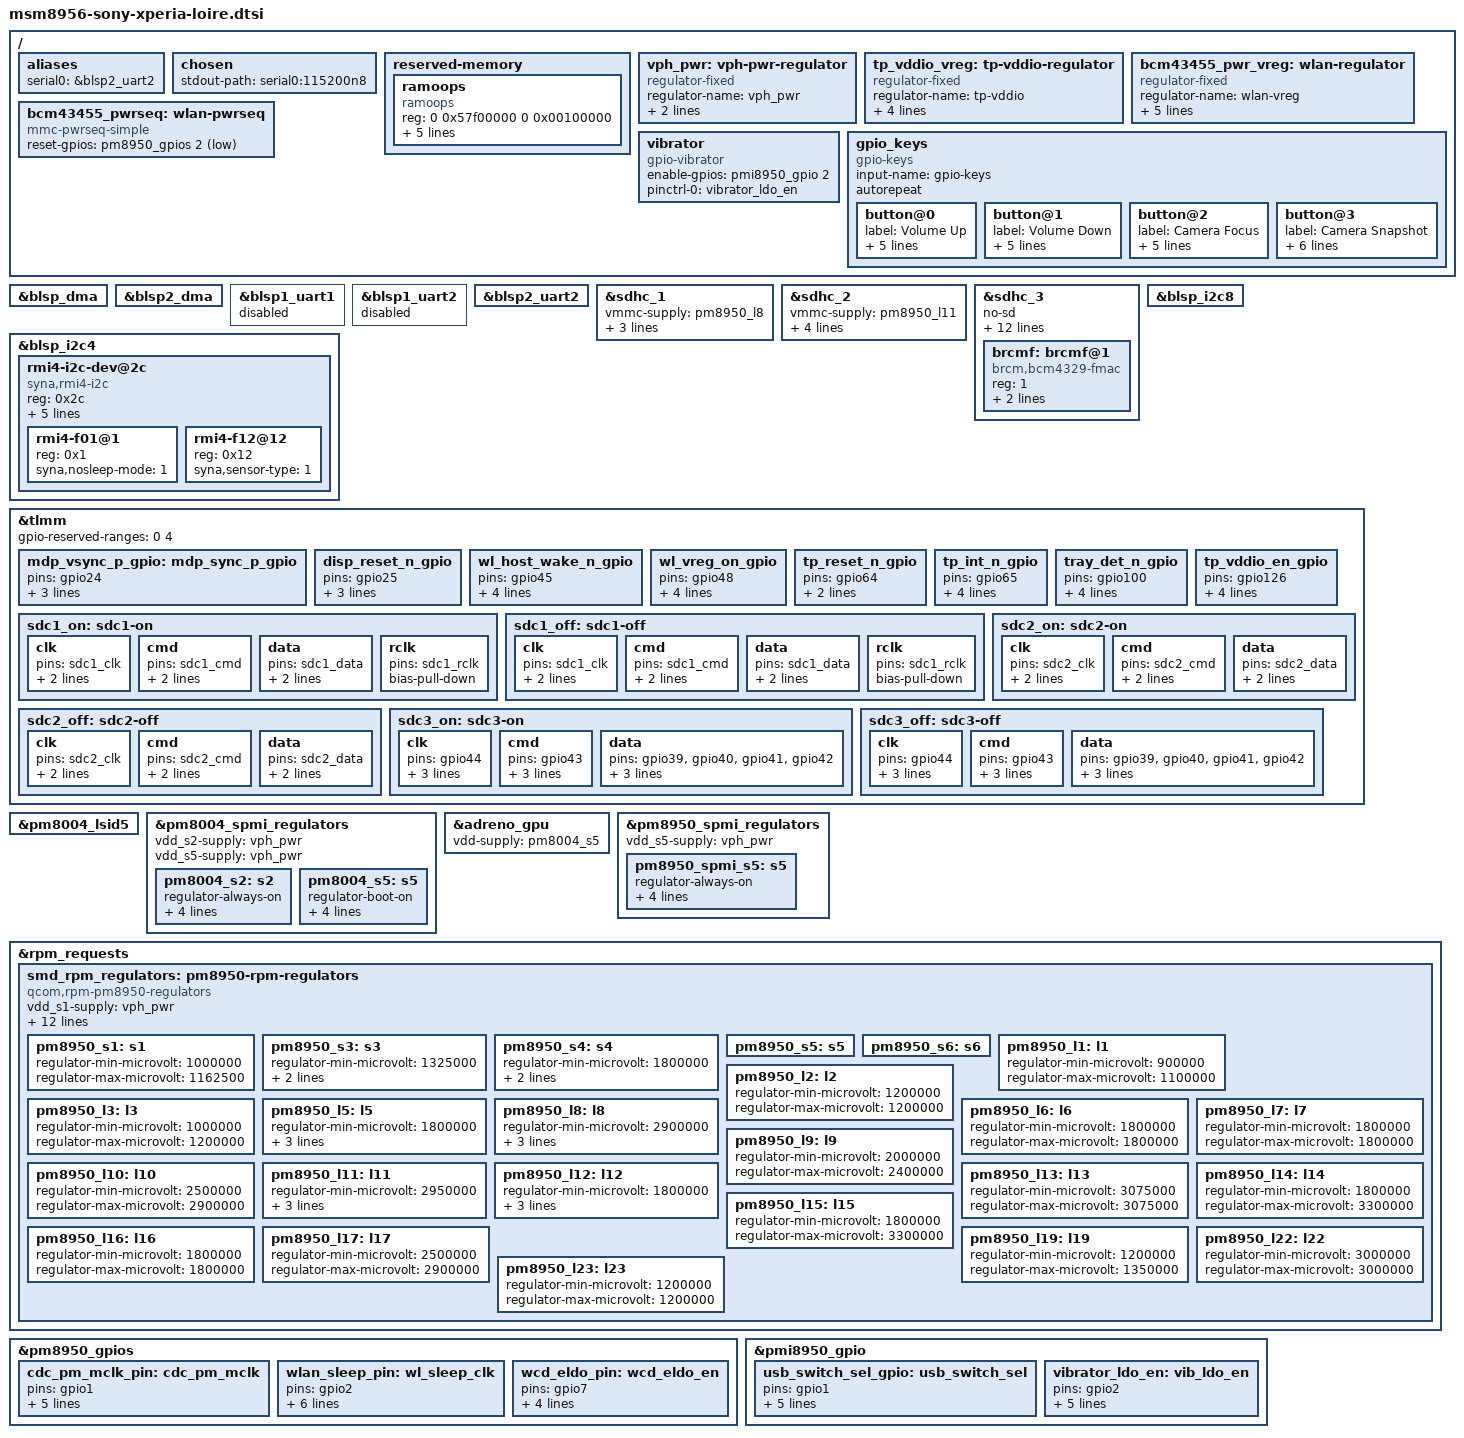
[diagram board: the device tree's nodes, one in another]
// SPDX-License-Identifier: GPL-2.0
/*
 * Sony Xperia Loire/SmartLoire platform (MSM8956/APQ8056) configuration
 * This configuration is common across a range of Xperia devices
 * based on the Loire and SmartLoire projects.
 *
 * Copyright (C) 2014 Sony Mobile Communications Inc.
 * Copyright (c) 2016-2019 AngeloGioacchino Del Regno <kholk11@gmail.com>
 */

#include "msm8976.dtsi"
#include "pmi8950.dtsi"
#include "pm8950.dtsi"
#include "pm8004.dtsi"
#include <dt-bindings/interrupt-controller/irq.h>
#include <dt-bindings/gpio/gpio.h>
#include <dt-bindings/input/gpio-keys.h>
#include <dt-bindings/input/input.h>
#include <dt-bindings/input/linux-event-codes.h>
#include <dt-bindings/pinctrl/qcom,pmic-gpio.h>

/ {
	aliases {
		serial0 = &blsp2_uart2;
	};

	chosen {
		stdout-path = "serial0:115200n8";
	};

	reserved-memory {
		ramoops {
			compatible = "ramoops";
			reg = <0 0x57f00000 0 0x00100000>;
			record-size = <0x20000>;
			console-size = <0x40000>;
			ftrace-size = <0x20000>;
			pmsg-size = <0x20000>;
			ecc-size = <16>;
			status = "ok";
		};
	};

	vph_pwr: vph-pwr-regulator {
		compatible = "regulator-fixed";
		regulator-name = "vph_pwr";
		regulator-always-on;
		regulator-boot-on;
	};

	tp_vddio_vreg: tp-vddio-regulator {
		compatible = "regulator-fixed";

		regulator-name = "tp-vddio";
		regulator-min-microvolt = <1800000>;
		regulator-max-microvolt = <1800000>;

		gpio = <&tlmm 126 GPIO_ACTIVE_HIGH>;

		pinctrl-names = "default";
		pinctrl-0 = <&tp_vddio_en_gpio>;
	};

	bcm43455_pwr_vreg: wlan-regulator {
		compatible = "regulator-fixed";

		regulator-name = "wlan-vreg";
		regulator-min-microvolt = <3300000>;
		regulator-max-microvolt = <3300000>;

		gpio = <&tlmm 48 GPIO_ACTIVE_HIGH>;
		enable-active-high;

		pinctrl-names = "default";
		pinctrl-0 = <&wl_vreg_on_gpio>;
	};

	bcm43455_pwrseq: wlan-pwrseq {
		compatible = "mmc-pwrseq-simple";
		reset-gpios = <&pm8950_gpios 2 GPIO_ACTIVE_LOW>;
	};

	vibrator {
		compatible = "gpio-vibrator";
		enable-gpios = <&pmi8950_gpio 2 GPIO_ACTIVE_HIGH>;

		pinctrl-names = "default";
		pinctrl-0 = <&vibrator_ldo_en>;
	};

	gpio_keys {
		compatible = "gpio-keys";
		input-name = "gpio-keys";
		#address-cells = <1>;
		#size-cells = <0>;
		autorepeat;

		button@0 {
			label = "Volume Up";
			gpios = <&tlmm 130 GPIO_ACTIVE_LOW>;
			linux,input-type = <EV_KEY>;
			linux,code = <KEY_VOLUMEUP>;
			wakeup-source;
			debounce-interval = <15>;
		};

		button@1 {
			label = "Volume Down";
			gpios = <&tlmm 113 GPIO_ACTIVE_LOW>;
			linux,input-type = <EV_KEY>;
			linux,code = <KEY_VOLUMEDOWN>;
			wakeup-source;
			debounce-interval = <15>;
		};

		button@2 {
			label = "Camera Focus";
			gpios = <&tlmm 114 GPIO_ACTIVE_LOW>;
			linux,input-type = <EV_KEY>;
			linux,code = <KEY_CAMERA_FOCUS>;
			wakeup-source;
			debounce-interval = <15>;
		};

		button@3 {
			label = "Camera Snapshot";
			gpios = <&tlmm 115 GPIO_ACTIVE_LOW>;
			linux,input-type = <EV_KEY>;
			linux,code = <KEY_CAMERA>;
			wakeup-source;
			wakeup-event-action = <EV_ACT_ASSERTED>;
			debounce-interval = <15>;
		};
	};
};

&blsp_dma {
	status = "ok";
};

&blsp2_dma {
	status = "ok";
};

&blsp1_uart1 {
	status = "disabled";
};

&blsp1_uart2 {
	status = "disabled";
};

&blsp2_uart2 {
	status = "ok";
};

/* eMMC */
&sdhc_1 {
	vmmc-supply = <&pm8950_l8>;
	vqmmc-supply = <&pm8950_l5>;

	pinctrl-names = "default", "sleep";
	pinctrl-0 = <&sdc1_on>;
	pinctrl-1 = <&sdc1_off>;

	status = "ok";
};

/* MicroSD card slot */
&sdhc_2 {
	vmmc-supply = <&pm8950_l11>;
	vqmmc-supply = <&pm8950_l12>;
	cd-gpios = <&tlmm 100 GPIO_ACTIVE_HIGH>;

	pinctrl-names = "default", "sleep";
	pinctrl-0 = <&sdc2_on &tray_det_n_gpio>;
	pinctrl-1 = <&sdc2_off &tray_det_n_gpio>;

	status = "ok";
};

/* SDIO (internal) to BCM WiFi */
&sdhc_3 {
	status = "ok";
	no-sd;
	no-mmc;

	bus-width = <4>;
	max-frequency = <100000000>;
	keep-power-in-suspend;

	non-removable;
	wakeup-source;
	vmmc-supply = <&bcm43455_pwr_vreg>;
	mmc-pwrseq = <&bcm43455_pwrseq>;

	pinctrl-names = "default", "sleep";
	pinctrl-0 = <&sdc3_on &wlan_sleep_pin &wl_host_wake_n_gpio>;
	pinctrl-1 = <&sdc3_off &wlan_sleep_pin &wl_host_wake_n_gpio>;

	#address-cells = <1>;
	#size-cells = <0>;

	brcmf: brcmf@1 {
		reg = <1>;
		compatible = "brcm,bcm4329-fmac";
		interrupt-parent = <&tlmm>;
		interrupts = <45 IRQ_TYPE_LEVEL_LOW>;
		interrupt-names = "host-wake";
	};
};

&blsp_i2c4 {
	status = "ok";

	rmi4-i2c-dev@2c {
		compatible = "syna,rmi4-i2c";
		reg = <0x2c>;

		interrupt-parent = <&tlmm>;
		interrupts = <65 IRQ_TYPE_EDGE_FALLING>;

		#address-cells = <1>;
		#size-cells = <0>;

		vdd-supply = <&tp_vddio_vreg>;

		syna,reset-delay-ms = <220>;
		syna,startup-delay-ms = <220>;

		rmi4-f01@1 {
			reg = <0x1>;
			syna,nosleep-mode = <1>;
		};

		rmi4-f12@12 {
			reg = <0x12>;
			syna,sensor-type = <1>;
		};
	};
};

&blsp_i2c8 {
	status = "ok";
};

&tlmm {
	gpio-reserved-ranges = <0 4>;

	mdp_vsync_p_gpio: mdp_sync_p_gpio {
		pins = "gpio24";
		function = "mdp_vsync";

		drive-strength = <2>;
		bias-disable;
	};

	disp_reset_n_gpio: disp_reset_n_gpio {
		pins = "gpio25";
		function = "gpio";

		drive-strength = <2>;
		output-high;
	};

	wl_host_wake_n_gpio: wl_host_wake_n_gpio {
		pins = "gpio45";
		function = "gpio";

		drive-strength = <2>;
		bias-pull-down;
		input-enable;
	};

	wl_vreg_on_gpio: wl_vreg_on_gpio {
		pins = "gpio48";
		function = "gpio";

		drive-strength = <2>;
		bias-disable;
		output-high;
	};

	tp_reset_n_gpio: tp_reset_n_gpio {
		pins = "gpio64";
		function = "gpio";

		drive-strength = <2>;
	};

	tp_int_n_gpio: tp_int_n_gpio {
		pins = "gpio65";
		function = "gpio";

		drive-strength = <2>;
		bias-pull-up;
		input-enable;
	};

	tray_det_n_gpio: tray_det_n_gpio {
		pins = "gpio100";
		function = "gpio";

		drive-strength = <2>;
		bias-disable;
		input-enable;
	};

	tp_vddio_en_gpio: tp_vddio_en_gpio {
		pins = "gpio126";
		function = "gpio";

		drive-strength = <2>;
		bias-disable;
		output-low;
	};

	sdc1_on: sdc1-on {
		clk {
			pins = "sdc1_clk";
			bias-disable;
			drive-strength = <16>;
		};

		cmd {
			pins = "sdc1_cmd";
			bias-pull-up;
			drive-strength = <10>;
		};

		data {
			pins = "sdc1_data";
			bias-pull-up;
			drive-strength = <10>;
		};

		rclk {
			pins = "sdc1_rclk";
			bias-pull-down;
		};
	};

	sdc1_off: sdc1-off {
		clk {
			pins = "sdc1_clk";
			bias-disable;
			drive-strength = <2>;
		};

		cmd {
			pins = "sdc1_cmd";
			bias-pull-up;
			drive-strength = <2>;
		};

		data {
			pins = "sdc1_data";
			bias-pull-up;
			drive-strength = <2>;
		};

		rclk {
			pins = "sdc1_rclk";
			bias-pull-down;
		};
	};

	sdc2_on: sdc2-on {
		clk {
			pins = "sdc2_clk";
			bias-disable;
			drive-strength = <16>;
		};

		cmd {
			pins = "sdc2_cmd";
			bias-pull-up;
			drive-strength = <10>;
		};

		data {
			pins = "sdc2_data";
			bias-pull-up;
			drive-strength = <10>;
		};
	};

	sdc2_off: sdc2-off {
		clk {
			pins = "sdc2_clk";
			bias-disable;
			drive-strength = <2>;
		};

		cmd {
			pins = "sdc2_cmd";
			bias-pull-up;
			drive-strength = <2>;
		};

		data {
			pins = "sdc2_data";
			bias-pull-up;
			drive-strength = <2>;
		};
	};

	sdc3_on: sdc3-on {
		clk {
			pins = "gpio44";
			function = "sdc3";
			bias-disable;
			drive-strength = <10>;
		};

		cmd {
			pins = "gpio43";
			function = "sdc3";
			bias-pull-up;
			drive-strength = <10>;
		};

		data {
			pins = "gpio39", "gpio40", "gpio41", "gpio42";
			function = "sdc3";
			bias-pull-up;
			drive-strength = <10>;
		};
	};

	sdc3_off: sdc3-off {
		clk {
			pins = "gpio44";
			function = "sdc3";
			bias-disable;
			drive-strength = <2>;
		};

		cmd {
			pins = "gpio43";
			function = "sdc3";
			bias-pull-up;
			drive-strength = <2>;
		};

		data {
			pins = "gpio39", "gpio40", "gpio41", "gpio42";
			function = "sdc3";
			bias-pull-up;
			drive-strength = <2>;
		};
	};
};

&pm8004_lsid5 {
	status = "ok";
};

&pm8004_spmi_regulators {
	vdd_s2-supply = <&vph_pwr>;
	vdd_s5-supply = <&vph_pwr>;

	/* Cluster 1 supply */
	pm8004_s2: s2 {
		/* Set APC1 always-on and raise min voltage to .95V
		 * until a proper CPU scaling solution lands
		 */
		regulator-always-on;
		regulator-boot-on;
		regulator-name = "vdd_apc1";
		regulator-min-microvolt = <950000>; /* 500000 */
		regulator-max-microvolt = <1165000>;
	};

	pm8004_s5: s5 {
		/* Put GFX VDD up at boot until a proper solution lands */
		regulator-boot-on;

		regulator-name = "vdd_gfx";
		regulator-min-microvolt = <950000>;
		regulator-max-microvolt = <1165000>;
		regulator-enable-ramp-delay = <500>;
	};
};

&adreno_gpu {
	vdd-supply = <&pm8004_s5>;
};

&pm8950_spmi_regulators {
	vdd_s5-supply = <&vph_pwr>;

	/* Cluster 0 supply */
	pm8950_spmi_s5: s5 {
		/* Set APC0 always-on and raise min voltage to .95V
		 * until a proper CPU scaling solution lands
		 */
		regulator-always-on;
		regulator-boot-on;
		regulator-name = "vdd_apc0";
		regulator-min-microvolt = <950000>; /* 790000 */
		regulator-max-microvolt = <1165000>;
	};
};

&rpm_requests {
	smd_rpm_regulators: pm8950-rpm-regulators {
		compatible = "qcom,rpm-pm8950-regulators";
	
		vdd_s1-supply = <&vph_pwr>;
		vdd_s2-supply = <&vph_pwr>;
		vdd_s3-supply = <&vph_pwr>;
		vdd_s4-supply = <&vph_pwr>;
		vdd_s5-supply = <&vph_pwr>;
		vdd_s6-supply = <&vph_pwr>;
		vdd_l1_l19-supply = <&pm8950_s3>;
		vdd_l2_l23-supply = <&pm8950_s3>;
		vdd_l3-supply = <&pm8950_s3>;
		vdd_l4_l5_l6_l7_l16-supply = <&pm8950_s4>;
		vdd_l8_l11_l12_l17_l22-supply = <&vph_pwr>;
		vdd_l20-supply = <&pm8950_s4>;
		vdd_l21-supply = <&pm8950_s4>;
	
		pm8950_s1: s1 {
			regulator-min-microvolt = <1000000>;
			regulator-max-microvolt = <1162500>;
		};
	
		pm8950_s3: s3 {
			regulator-min-microvolt = <1325000>;
			regulator-max-microvolt = <1325000>;
			regulator-always-on;
		};
	
		pm8950_s4: s4 {
			regulator-min-microvolt = <1800000>;
			regulator-max-microvolt = <1800000>;
			regulator-always-on;
		};
	
		pm8950_s5: s5 {};
	
		pm8950_s6: s6 {};
	
		pm8950_l1: l1 {
			regulator-min-microvolt = <900000>;
			regulator-max-microvolt = <1100000>;
		};
	
		pm8950_l2: l2 {
			regulator-min-microvolt = <1200000>;
			regulator-max-microvolt = <1200000>;
		};
	
		pm8950_l3: l3 {
			regulator-min-microvolt = <1000000>;
			regulator-max-microvolt = <1200000>;
		};
	
		pm8950_l5: l5 {
			regulator-min-microvolt = <1800000>;
			regulator-max-microvolt = <1800000>;
	
			regulator-system-load = <300000>;
			regulator-allow-set-load;
		};
	
		pm8950_l6: l6 {
			regulator-min-microvolt = <1800000>;
			regulator-max-microvolt = <1800000>;
		};
	
		pm8950_l7: l7 {
			regulator-min-microvolt = <1800000>;
			regulator-max-microvolt = <1800000>;
		};
	
		pm8950_l8: l8 {
			regulator-min-microvolt = <2900000>;
			regulator-max-microvolt = <2900000>;
	
			regulator-system-load = <550000>;
			regulator-allow-set-load;
		};
	
		pm8950_l9: l9 {
			regulator-min-microvolt = <2000000>;
			regulator-max-microvolt = <2400000>;
		};
	
		pm8950_l10: l10 {
			regulator-min-microvolt = <2500000>;
			regulator-max-microvolt = <2900000>;
		};
	
		pm8950_l11: l11 {
			regulator-min-microvolt = <2950000>;
			regulator-max-microvolt = <2950000>;
	
			regulator-system-load = <550000>;
			regulator-allow-set-load;
		};
	
		pm8950_l12: l12 {
			regulator-min-microvolt = <1800000>;
			regulator-max-microvolt = <2950000>;
	
			regulator-system-load = <22000>;
			regulator-allow-set-load;
		};
	
		pm8950_l13: l13 {
			regulator-min-microvolt = <3075000>;
			regulator-max-microvolt = <3075000>;
		};
	
		pm8950_l14: l14 {
			regulator-min-microvolt = <1800000>;
			regulator-max-microvolt = <3300000>;
		};
	
		pm8950_l15: l15 {
			regulator-min-microvolt = <1800000>;
			regulator-max-microvolt = <3300000>;
		};
	
		pm8950_l16: l16 {
			regulator-min-microvolt = <1800000>;
			regulator-max-microvolt = <1800000>;
		};
	
		pm8950_l17: l17 {
			regulator-min-microvolt = <2500000>;
			regulator-max-microvolt = <2900000>;
		};
	
		pm8950_l19: l19 {
			regulator-min-microvolt = <1200000>;
			regulator-max-microvolt = <1350000>;
		};
	
		pm8950_l22: l22 {
			regulator-min-microvolt = <3000000>;
			regulator-max-microvolt = <3000000>;
		};
	
		pm8950_l23: l23 {
			regulator-min-microvolt = <1200000>;
			regulator-max-microvolt = <1200000>;
		};
	};
};

&pm8950_gpios {
	cdc_pm_mclk_pin: cdc_pm_mclk {
		pins = "gpio1";
		function = PMIC_GPIO_FUNC_FUNC1; /* SF1 */
		output-low;
		bias-disable;
		qcom,drive-strength = <PMIC_GPIO_STRENGTH_MED>;
		power-source = <2>; /* VIN 2 */
	};

	wlan_sleep_pin: wl_sleep_clk {
		pins = "gpio2";
		function = PMIC_GPIO_FUNC_FUNC1; /* SF1 SLEEP_CLK2 */
		output-high;
		bias-disable;
		drive-push-pull;
		qcom,drive-strength = <PMIC_GPIO_STRENGTH_HIGH>;
		power-source = <0>; /* VPH_PWR */
	};

	wcd_eldo_pin: wcd_eldo_en {
		pins = "gpio7";
		function = "gpio";
		output-low;
		bias-disable;
		power-source = <0>; /* VPH_PWR */
	};
};

&pmi8950_gpio {
	usb_switch_sel_gpio: usb_switch_sel {
		pins = "gpio1";
		function = PMIC_GPIO_FUNC_NORMAL;
		output-low;
		drive-push-pull;
		qcom,drive-strength = <PMIC_GPIO_STRENGTH_HIGH>;
		power-source = <0>;
	};

	vibrator_ldo_en: vib_ldo_en {
		pins = "gpio2";
		function = PMIC_GPIO_FUNC_NORMAL;
		output-low;
		drive-push-pull;
		qcom,drive-strength = <PMIC_GPIO_STRENGTH_HIGH>;
		power-source = <0>;
	};
};
